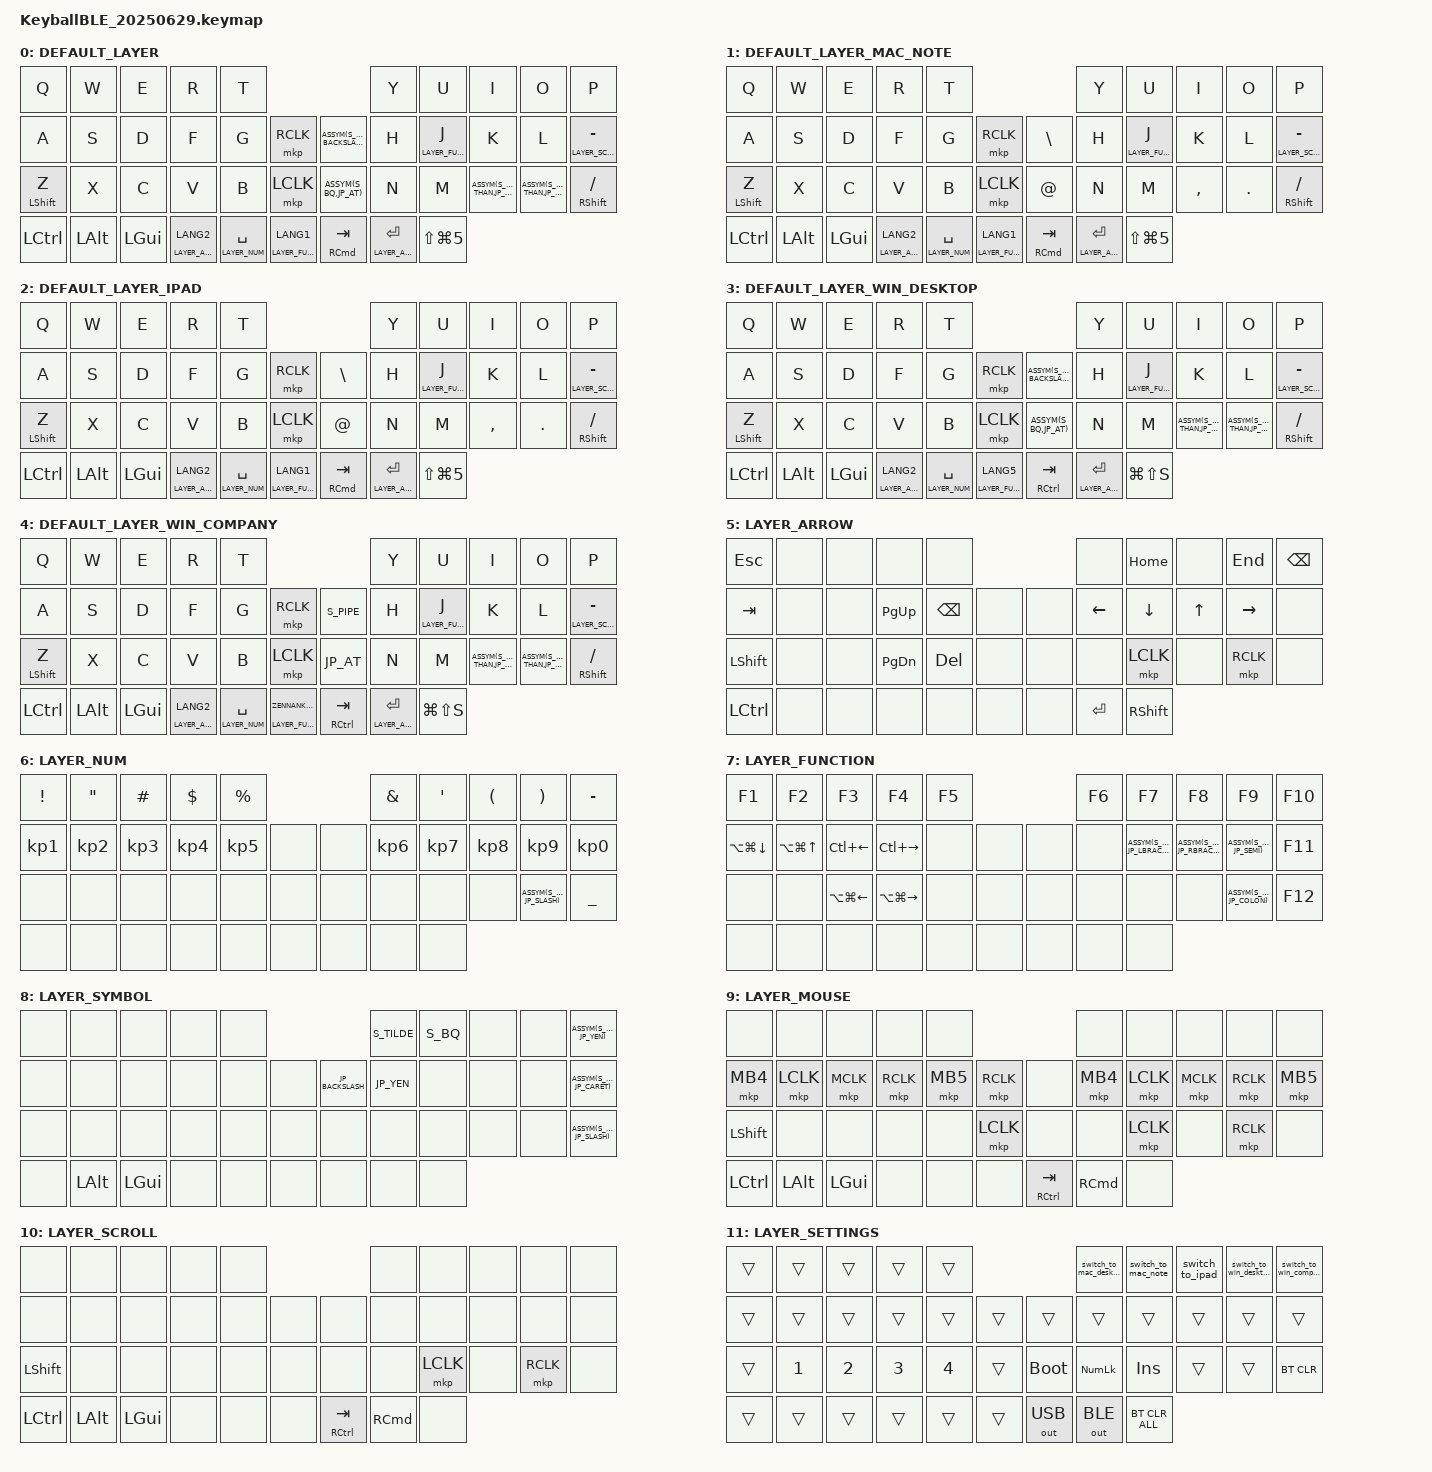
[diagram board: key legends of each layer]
#define ZMK_POINTING_DEFAULT_SCRL_VAL 120    // default: 10

// レイヤー定義
// デフォルトレイヤー (接続先ごと)

#define DEFAULT_LAYER 0  // デスクトップMac用
#define DEFAULT_LAYER_MAC_NOTE 1     // ノートMac用
#define DEFAULT_LAYER_IPAD 2         // iPad用
#define DEFAULT_LAYER_WIN_DESKTOP 3  // デスクトップWin用
#define DEFAULT_LAYER_WIN_COMPANY 4  // 会社用Win用

// 機能レイヤー

#define LAYER_ARROW 5      // 矢印キーレイヤー
#define LAYER_NUM 6   // 数字キーレイヤー
#define LAYER_FUNCTION 7   // ファンクションキーレイヤー
#define LAYER_SYMBOL 8     // 記号レイヤー
#define LAYER_MOUSE 9      // マウス操作レイヤー
#define LAYER_SCROLL 10     // スクロールレイヤー
#define LAYER_SETTINGS 11  // 設定レイヤー

// 接続先ごとのデフォルトレイヤーを定義
#define BT_PROFILE_0 DEFAULT_LAYER  // 接続先1: デスクトップMac
#define BT_PROFILE_1 DEFAULT_LAYER_MAC_NOTE     // 接続先2: ノートMac
#define BT_PROFILE_2 DEFAULT_LAYER_IPAD         // 接続先3: iPad
#define BT_PROFILE_3 DEFAULT_LAYER_WIN_DESKTOP  // 接続先4: デスクトップWin
#define BT_PROFILE_4 DEFAULT_LAYER_WIN_COMPANY  // 接続先5: 会社用Win

#include <behaviors.dtsi>
#include <dt-bindings/zmk/bt.h>
#include <dt-bindings/zmk/keys.h>
#include <dt-bindings/zmk/outputs.h>    //USB/BT切替設定のため
#include <dt-bindings/zmk/pointing.h>
#include <input/processors.dtsi>
//USコードをJISに変えるコード
#include "boards/shields/Test/code.h"

// Autoshift Macro（記号利用、通常キーは影響が大きいため）
#define ASSYM(shifted, keycode) &auto_shift shifted keycode

//#define MOUSE 4
//#define SCROLL 5
//#define NUM 6

//AML関連設定
&zip_temp_layer {
    excluded-positions = <
        30 // M
        32 // .
        34 // LEFT_CONTROL
        //Macro対応のため不要 18 // J
        //Macro対応のため不要 22 // LEFT_SHIFT
        //Macro対応のため不要 33 // RIGHT_SHIFT
        //Macro対応のため不要 41 // RIGHT_COMMAND
    >;
};

//キー入力から一定時間はAMLを発動しない
&zip_temp_layer {
    require-prior-idle-ms = <200>;
};
//マウスキーを押したらタイムアウトを延長する
&mkp_input_listener {
    input-processors = <&zip_temp_layer 9 10000>;
};
//マウスキーを押すまでマウスレイヤーに留まる(マウスキーを押したらタイムアウトを延長すると同じ実装で、タイムアウト時間が違うだけ)
&mkp_input_listener {
    input-processors = <&zip_temp_layer 9 250>;
};


&mt {
    flavor = "balanced";
    quick-tap-ms = <0>;
};

/ {
    combos {
        compatible = "zmk,combos";

        double_quotation {
            bindings = <&kp DOUBLE_QUOTES>;
            key-positions = <20 21>;
        };

        To_LayerARROW {
            bindings = <&mo LAYER_ARROW>;  // ARROWレイヤーに移動
            key-positions = <11 12>;
        };

        To_LayerSYMBOL {
            bindings = <&mo LAYER_SYMBOL>;  // SYMBOLレイヤーに移動
            key-positions = <23 24>;
        };

        To_LayerSETTING {
            bindings = <&mo LAYER_SETTINGS>;  // 設定レイヤーに移動
            //combo-term-ms = 30;
            key-positions = <38 37>;
        };

        chk_keynum1 {
            bindings = <&none>;
            key-positions = <0 10>;
        };

        chk_keynum2 {
            bindings = <&none>;
            key-positions = <9 21>;
        };

        chk_keynum3 {
            bindings = <&none>;
            key-positions = <22 34>;
        };

        chk_keynum4 {
            bindings = <&none>;
            key-positions = <41 42>;
        };
    };

    macros {
        // 接続先切り替えマクロ

        switch_to_mac_desktop: switch_to_mac_desktop {
            compatible = "zmk,behavior-macro";
            #binding-cells = <0>;
            bindings = <&tog_off DEFAULT_LAYER_MAC_NOTE &tog_off DEFAULT_LAYER_IPAD &tog_off DEFAULT_LAYER_WIN_DESKTOP &tog_off DEFAULT_LAYER_WIN_COMPANY &bt BT_SEL 0 &tog_on DEFAULT_LAYER>;
            label = "SWITCH_TO_MAC_DESKTOP";
        };

        switch_to_mac_note: switch_to_mac_note {
            compatible = "zmk,behavior-macro";
            #binding-cells = <0>;
            bindings = <&tog_off DEFAULT_LAYER &tog_off DEFAULT_LAYER_IPAD &tog_off DEFAULT_LAYER_WIN_DESKTOP &tog_off DEFAULT_LAYER_WIN_COMPANY &bt BT_SEL 1 &tog_on DEFAULT_LAYER_MAC_NOTE>;
            label = "SWITCH_TO_MAC_NOTE";
        };

        switch_to_ipad: switch_to_ipad {
            compatible = "zmk,behavior-macro";
            #binding-cells = <0>;
            bindings = <&tog_off DEFAULT_LAYER &tog_off DEFAULT_LAYER_MAC_NOTE &tog_off DEFAULT_LAYER_WIN_DESKTOP &tog_off DEFAULT_LAYER_WIN_COMPANY &bt BT_SEL 2 &tog_on DEFAULT_LAYER_IPAD>;
            label = "SWITCH_TO_IPAD";
        };

        switch_to_win_desktop: switch_to_win_desktop {
            compatible = "zmk,behavior-macro";
            #binding-cells = <0>;
            bindings = <&tog_off DEFAULT_LAYER &tog_off DEFAULT_LAYER_MAC_NOTE &tog_off DEFAULT_LAYER_IPAD &tog_off DEFAULT_LAYER_WIN_COMPANY &bt BT_SEL 3 &tog_on DEFAULT_LAYER_WIN_DESKTOP>;
            label = "SWITCH_TO_WIN_DESKTOP";
        };

        switch_to_win_company: switch_to_win_company {
            compatible = "zmk,behavior-macro";
            #binding-cells = <0>;
            bindings = <&tog_off DEFAULT_LAYER &tog_off DEFAULT_LAYER_MAC_NOTE &tog_off DEFAULT_LAYER_IPAD &tog_off DEFAULT_LAYER_WIN_DESKTOP &bt BT_SEL 4 &tog_on DEFAULT_LAYER_WIN_COMPANY>;
            label = "SWITCH_TO_WIN_COMPANY";
        };

        to_default_layer: to_default_layer {
            compatible = "zmk,behavior-macro";
            #binding-cells = <0>;
            bindings = <&to DEFAULT_LAYER &to DEFAULT_LAYER_MAC_NOTE &to DEFAULT_LAYER_IPAD &to DEFAULT_LAYER_WIN_DESKTOP &to DEFAULT_LAYER_WIN_COMPANY>;
            label = "TO_DEFAULT_LAYER";
        };

        to_layer_df: to_layer_df {
            compatible = "zmk,behavior-macro-one-param";
            #binding-cells = <1>;
            bindings = <&to &to_default_layer &macro_param_1to1 &kp MACRO_PLACEHOLDER>;
            label = "TO_LAYER_df";
        };

        Mac_screenshot: Mac_screenshot {
            compatible = "zmk,behavior-macro";
            #binding-cells = <0>;
            bindings = <&kp LS(LG(KP_NUMBER_5))>;
            label = "MAC_SCREENSHOT";
        };

        //AML関連設定
        exit_AML: exit_AML {
            compatible = "zmk,behavior-macro";
            wait-ms = <0>;
            tap-ms = <0>;
            #binding-cells = <0>;
            bindings = <&tog_off LAYER_MOUSE>;
            label = "exit_AML";
        };

        kp_exit_AML: kp_exit_AML {
            compatible = "zmk,behavior-macro-one-param";
            wait-ms = <0>;
            tap-ms = <0>;
            #binding-cells = <1>;
            bindings = <&macro_param_1to1 &kp MACRO_PLACEHOLDER &exit_AML>;
            label = "KP_exit_AML";
        };
    };

    behaviors {
        lt_to_layer_0: lt_to_layer_0 {
            compatible = "zmk,behavior-hold-tap";
            label = "LAYER_TAP_TO_0";
            bindings = <&mo>, <&to_layer_df>;

            #binding-cells = <2>;
            tapping-term-ms = <200>;
        };

        tog_on: toggle_layer_on_only {
            compatible = "zmk,behavior-toggle-layer";
            #binding-cells = <1>;
            display-name = "Toggle Layer On";
            toggle-mode = "on";
        };

        tog_off: toggle_layer_off_only {
            compatible = "zmk,behavior-toggle-layer";
            #binding-cells = <1>;
            display-name = "Toggle Layer Off";
            toggle-mode = "off";
        };

        ROTATE: ROTATE {
            compatible = "zmk,behavior-sensor-rotate-var";
            label = "ROTATE";
            #sensor-binding-cells = <2>;
            bindings = <&msc>, <&msc>;

            tap-ms = <20>;
        };

        scroll_up_down: behavior_sensor_rotate_mouse_wheel_up_down {
            compatible = "zmk,behavior-sensor-rotate";
            #sensor-binding-cells = <0>;
            bindings = <&msc SCRL_UP>, <&msc SCRL_DOWN>;

            tap-ms = <20>;
        };

        //AML   
        mt_exit_AML_on_tap: mt_exit_AML_on_tap {
            compatible = "zmk,behavior-hold-tap";
            label = "MT_exit_AML_ON_TAP";
            bindings = <&kp>, <&kp_exit_AML>;

            #binding-cells = <2>;
            tapping-term-ms = <200>;
            flavor = "balanced";
            quick-tap-ms = <200>;
        };

        //AutoShift
        auto_shift: auto_shift {
            compatible = "zmk,behavior-hold-tap";
            #binding-cells = <2>;
            tapping_term_ms = <200>;
            quick_tap_ms = <0>;
            flavor = "hold-preferred";
            bindings = <&kp>, <&kp>;
        };
    };

    keymap {
        compatible = "zmk,keymap";

        DEFAULT_LAYER {
            bindings = <
&kp Q             &kp W         &kp E         &kp R                  &kp T                                                                     &kp Y                  &kp U                 &kp I      &kp O    &kp P
&kp A             &kp S         &kp D         &kp F                  &kp G                &mkp RCLK                         ASSYM(S_UNDERSCORE,JP_BACKSLASH)     &kp H                  &lt LAYER_FUNCTION J  &kp K      &kp L    &lt LAYER_SCROLL MINUS
&mt LEFT_SHIFT Z  &kp X         &kp C         &kp V                  &kp B                &mkp LCLK                         ASSYM(S_BQ,JP_AT) &kp N                  &kp M                ASSYM(S_LESS_THAN,JP_COMMA)  ASSYM(S_GREATER_THAN,JP_DOT)  &mt RIGHT_SHIFT SLASH
&kp LCTRL         &kp LEFT_ALT  &kp LEFT_GUI  &lt LAYER_ARROW LANG2     &lt LAYER_NUM SPACE     &lt LAYER_FUNCTION LANG1        &mt RIGHT_COMMAND TAB     &lt LAYER_ARROW ENTER   &kp LS(LG(N5))

            >;

            sensor-bindings = <&ROTATE SCRL_DOWN SCRL_UP>;
        };

        DEFAULT_LAYER_MAC_NOTE {
            bindings = <
&kp Q             &kp W         &kp E         &kp R                  &kp T                                                                     &kp Y                  &kp U                 &kp I      &kp O    &kp P
&kp A             &kp S         &kp D         &kp F                  &kp G                &mkp RCLK                     &kp BACKSLASH          &kp H                  &lt LAYER_FUNCTION J  &kp K      &kp L    &lt LAYER_SCROLL MINUS
&mt LEFT_SHIFT Z  &kp X         &kp C         &kp V                  &kp B                &mkp LCLK                     &kp AT_SIGN            &kp N                  &kp M                 &kp COMMA  &kp DOT  &mt RIGHT_SHIFT SLASH
&kp LCTRL         &kp LEFT_ALT  &kp LEFT_GUI  &lt LAYER_ARROW LANG2  &lt LAYER_NUM SPACE  &lt LAYER_FUNCTION LANG1      &mt RIGHT_COMMAND TAB  &lt LAYER_ARROW ENTER                                            &kp LS(LG(N5))
            >;

            sensor-bindings = <&ROTATE SCRL_DOWN SCRL_UP>;
        };

        DEFAULT_LAYER_IPAD {
            bindings = <
&kp Q             &kp W         &kp E         &kp R                  &kp T                                                                     &kp Y                  &kp U                 &kp I      &kp O    &kp P
&kp A             &kp S         &kp D         &kp F                  &kp G                &mkp RCLK                     &kp BACKSLASH          &kp H                  &lt LAYER_FUNCTION J  &kp K      &kp L    &lt LAYER_SCROLL MINUS
&mt LEFT_SHIFT Z  &kp X         &kp C         &kp V                  &kp B                &mkp LCLK                     &kp AT_SIGN            &kp N                  &kp M                 &kp COMMA  &kp DOT  &mt RIGHT_SHIFT SLASH
&kp LCTRL         &kp LEFT_ALT  &kp LEFT_GUI  &lt LAYER_ARROW LANG2  &lt LAYER_NUM SPACE  &lt LAYER_FUNCTION LANG1      &mt RIGHT_COMMAND TAB  &lt LAYER_ARROW ENTER                                            &kp LS(LG(N5))
            >;

            sensor-bindings = <&ROTATE SCRL_DOWN SCRL_UP>;
        };

        DEFAULT_LAYER_WIN_DESKTOP {
            bindings = <
&kp Q             &kp W         &kp E         &kp R                  &kp T                                                   &kp Y                               &kp U                 &kp I      &kp O    &kp P
&kp A             &kp S         &kp D         &kp F                  &kp G                &mkp RCLK                         ASSYM(S_UNDERSCORE,JP_BACKSLASH)     &kp H                  &lt LAYER_FUNCTION J  &kp K      &kp L    &lt LAYER_SCROLL MINUS
&mt LEFT_SHIFT Z  &kp X         &kp C         &kp V                  &kp B                &mkp LCLK                         ASSYM(S_BQ,JP_AT) &kp N              &kp M                ASSYM(S_LESS_THAN,JP_COMMA)  ASSYM(S_GREATER_THAN,JP_DOT)  &mt RIGHT_SHIFT SLASH
&kp LCTRL         &kp LEFT_ALT  &kp LEFT_GUI  &lt LAYER_ARROW LANG2  &lt LAYER_NUM SPACE  &lt LAYER_FUNCTION LANG5      &mt RCTRL TAB  &lt LAYER_ARROW ENTER                                            &kp LG(LS(S))
            >;

            sensor-bindings = <&ROTATE SCRL_DOWN SCRL_UP>;
        };

        DEFAULT_LAYER_WIN_COMPANY {
            bindings = <
&kp Q             &kp W         &kp E         &kp R                  &kp T                                                  &kp Y                                &kp U                 &kp I      &kp O    &kp P
&kp A             &kp S         &kp D         &kp F                  &kp G                &mkp RCLK                         &kp S_PIPE     &kp H                  &lt LAYER_FUNCTION J  &kp K      &kp L    &lt LAYER_SCROLL MINUS
&mt LEFT_SHIFT Z  &kp X         &kp C         &kp V                  &kp B                &mkp LCLK                         &kp JP_AT      &kp N              &kp M                ASSYM(S_LESS_THAN,JP_COMMA)  ASSYM(S_GREATER_THAN,JP_DOT)  &mt RIGHT_SHIFT SLASH
&kp LCTRL         &kp LEFT_ALT  &kp LEFT_GUI  &lt LAYER_ARROW LANG2  &lt LAYER_NUM SPACE  &lt LAYER_FUNCTION ZENNANKAKU     &mt RCTRL TAB  &lt LAYER_ARROW ENTER                                            &kp LG(LS(S))
            >;

            sensor-bindings = <&ROTATE SCRL_DOWN SCRL_UP>;
        };

        LAYER_ARROW {
            bindings = <
&kp ESCAPE        &none  &none  &none          &none                            &none     &kp HOME        &none         &kp END          &kp BACKSPACE
&kp TAB           &none  &none  &kp PAGE_UP    &kp BACKSPACE  &none      &none  &kp LEFT  &kp DOWN_ARROW  &kp UP_ARROW  &kp RIGHT_ARROW  &none
&kp LEFT_SHIFT    &none  &none  &kp PAGE_DOWN  &kp DELETE     &none      &none  &none     &mkp LCLK       &none         &mkp RCLK        &none
&kp LEFT_CONTROL  &none  &none  &none          &none          &none      &none  &kp ENTER                                                    &kp RIGHT_SHIFT
            >;
        };

        LAYER_NUM {
            bindings = <
&kp EXCLAMATION  &kp DOUBLE_QUOTES  &kp HASH         &kp DOLLAR       &kp PERCENT                        &kp AMPERSAND    &kp SQT          &kp LEFT_PARENTHESIS  &kp RIGHT_PARENTHESIS  &kp MINUS
&kp KP_NUMBER_1  &kp KP_NUMBER_2    &kp KP_NUMBER_3  &kp KP_NUMBER_4  &kp KP_NUMBER_5  &none      &none  &kp KP_NUMBER_6  &kp KP_NUMBER_7  &kp KP_NUMBER_8       &kp KP_NUMBER_9        &kp KP_NUMBER_0
&none        &none          &none        &none        &none        &none      &none  &none            &none     &none             ASSYM(S_QUESTION, JP_SLASH)                   &kp UNDERSCORE
&none        &none              &none            &none            &none            &none      &none  &none                                                                          &none
            >;
        };

        LAYER_FUNCTION {
            bindings = <
&kp F1                  &kp F2                &kp F3                  &kp F4                   &kp F5                    &kp F6  &kp F7                &kp F8                 &kp F9         &kp F10
&kp LA(LG(DOWN_ARROW))  &kp LA(LG(UP_ARROW))  &kp LC(LEFT_ARROW)      &kp LC(RIGHT_ARROW)      &none   &none      &none  &none   ASSYM(S_LBRACKET, JP_LBRACKET)  ASSYM(S_RBRACKET, JP_RBRACKET)  ASSYM(S_PLUS, JP_SEMI)  &kp F11
&none          &none                 &kp LA(LG(LEFT_ARROW))  &kp LA(LG(RIGHT_ARROW))  &none   &none      &none  &none   &none  &none  ASSYM(S_ASTERISK, JP_COLON)  &kp F12
&none               &none                 &none                   &none                    &none   &none      &none  &none                                                               &none
            >;

            sensor-bindings = <&inc_dec_kp LC(PAGE_UP) LC(PAGE_DOWN)>;
        };

        LAYER_SYMBOL {
            bindings = <
&none  &none  &none  &none  &none                      &kp S_TILDE   &kp S_BQ  &none   &none           ASSYM(S_PIPE, JP_YEN)
&none  &none  &none  &none  &none  &none               &kp JP_BACKSLASH   &kp JP_YEN  &none   &none    &none  ASSYM(S_TILDE, JP_CARET)
&none  &none  &none  &none  &none  &none               &none   &none  &none   &none    &none  ASSYM(S_QUESTION, JP_SLASH)
&none     &kp LEFT_ALT  &kp LEFT_GUI  &none  &none  &none      &none  &none                          &none
            >;
        };

        LAYER_MOUSE {
            bindings = <
&none     &none      &none      &none      &none                           &none     &none      &none      &none      &none
&mkp MB4  &mkp LCLK  &mkp MCLK  &mkp RCLK  &mkp MB5  &mkp RCLK      &none  &mkp MB4  &mkp LCLK  &mkp MCLK  &mkp RCLK  &mkp MB5
&kp LEFT_SHIFT     &none      &none      &none      &none     &mkp LCLK      &none  &none     &mkp LCLK  &none      &mkp RCLK  &none
&kp LCTRL     &kp LEFT_ALT  &kp LEFT_GUI  &none  &none  &none      &mt RCTRL TAB  &kp RIGHT_COMMAND                          &none
            >;
        };

        LAYER_SCROLL {
            bindings = <
&none  &none  &none  &none  &none                    &none  &none  &none  &none  &none
&none  &none  &none  &none  &none  &none      &none  &none  &none  &none  &none  &none
&kp LEFT_SHIFT  &none  &none  &none  &none  &none      &none  &none  &mkp LCLK       &none         &mkp RCLK  &none
&kp LCTRL     &kp LEFT_ALT  &kp LEFT_GUI  &none  &none  &none      &mt RCTRL TAB  &kp RIGHT_COMMAND                          &none
            >;

            sensor-bindings = <&scroll_up_down>;  // スクロール用のセンサーバインディング
        };

        LAYER_SETTINGS {
            bindings = <
&trans  &trans        &trans        &trans        &trans                            &switch_to_mac_desktop  &switch_to_mac_note  &switch_to_ipad  &switch_to_win_desktop  &switch_to_win_company
&trans  &trans        &trans        &trans        &trans  &trans      &trans        &trans                  &trans               &trans           &trans                  &trans
&trans  &kp NUMBER_1  &kp NUMBER_2  &kp NUMBER_3  &kp N4  &trans      &bootloader   &kp KP_NUMLOCK          &kp INS              &trans           &trans                  &bt BT_CLR
&trans  &trans        &trans        &trans        &trans  &trans      &out OUT_USB  &out OUT_BLE                                                                          &bt BT_CLR_ALL
            >;
        };
    };
};
